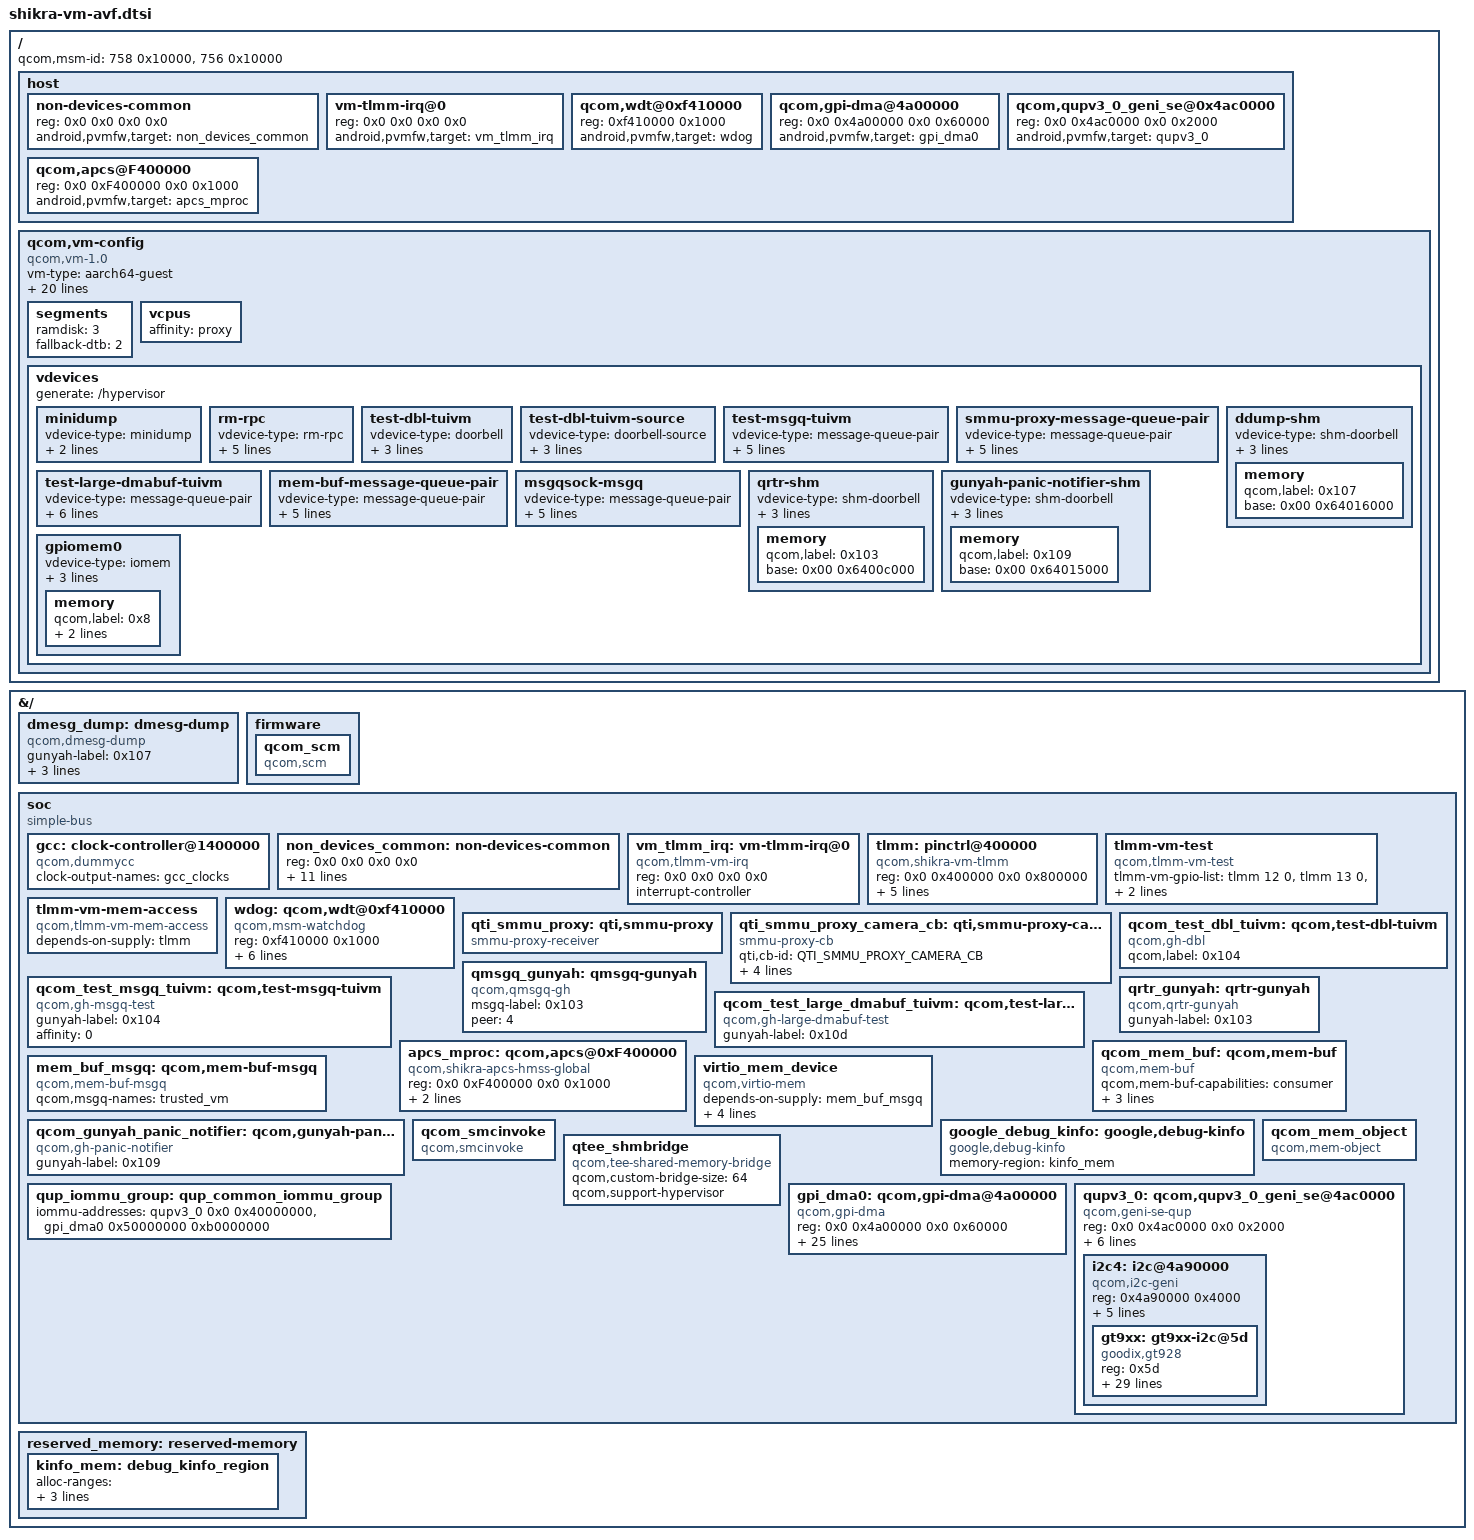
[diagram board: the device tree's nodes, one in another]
// SPDX-License-Identifier: BSD-3-Clause
/*
 * Copyright (c) Qualcomm Technologies, Inc. and/or its subsidiaries.
 */

#include <dt-bindings/interrupt-controller/arm-gic.h>
#include <dt-bindings/arm/msm/qti-smmu-proxy-dt-ids.h>
#include <dt-bindings/clock/qcom,shikra-gcc.h>
#include <dt-bindings/dma/qcom-gpi.h>

/ {
	#address-cells = <0x2>;
	#size-cells = <0x2>;
	qcom,msm-id = <758 0x10000>, <756 0x10000>;

	host {
		#address-cells = <0x2>;
		#size-cells = <0x2>;

		non-devices-common {
			reg = <0x0 0x0 0x0 0x0>;
			android,pvmfw,target = <&non_devices_common>;
		};

		vm-tlmm-irq@0 {
			reg = <0x0 0x0 0x0 0x0>;
			android,pvmfw,target = <&vm_tlmm_irq>;
		};

		qcom,wdt@0xf410000 { // APSS_WDT_TMR1_APSS_WDT
			reg = <0xf410000 0x1000>;
			android,pvmfw,target = <&wdog>;
		};

		qcom,gpi-dma@4a00000 {
			reg = <0x0 0x4a00000 0x0 0x60000>;
			android,pvmfw,target = <&gpi_dma0>;
		};

		qcom,qupv3_0_geni_se@0x4ac0000 {
			reg=<0x0 0x4ac0000 0x0 0x2000>;
			android,pvmfw,target = <&qupv3_0>;
		};

		qcom,apcs@F400000 {
			reg = <0x0 0xF400000 0x0 0x1000>;
			android,pvmfw,target = <&apcs_mproc>;
		};
	};

	qcom,vm-config {
		compatible = "qcom,vm-1.0";
		vm-type = "aarch64-guest";
		boot-config = "fdt,unified";
		// Guest OS
		os-type = "linux";
		kernel-entry-segment = "kernel";
		kernel-entry-offset = <0x0 0x0>;
		vendor = "QTI";
		image-name = "qcom,trustedvm";
		// PIL SW-ID , mandatory for PIL authentication
		qcom,pasid = <0x0 0x1c>;
		// Information for TZ client registration
		qcom,qtee-config-info = "p=3,9,C,39,77,78,7C,8F,96,97,C8,FE,10C,11B,159,199,47E,7F1,CDF;";
		// VMID
		qcom,secdomain-ids = <45>;
		// Index of primary secdomain-id, if qcom,secdomain-ids property present
		qcom,primary-vm-index = <0>;
		vm-uri = "vmuid/trusted-ui";
		// A unique ID that can be used by clients to identify a VM image
		vm-guid = "598085da-c516-5b25-a9c1-927a02819770";
		// Optional – tag VM as sensitive
		qcom,sensitive;

		vm-attrs = "context-dump", "crash-restart", "no-vpm-aggregation";

		/* GPII - 8 is used for QUP LEVM case */
		iomemory-ranges = <0x0 0xF400000 0x0 0xF400000 0x0 0x1000 0x0
				0x0 0x4a30000 0x0 0x4a30000 0x0 0x4000 0x0>;

		/* Dynamically nominate the vmmio ranges */
		vmmio-ranges;

		/* QUP0: SE4: GPII8 : GIC_SPI IRQ 519 + 32 = 551 */
		gic-irq-ranges = <327 327
				551 551>;

		segments {
			ramdisk = <3>;
			// fallback-dtb to support recovery mode
			fallback-dtb = <2>;
		};

		vcpus {
			affinity = "proxy";
		};

		vdevices {
			generate = "/hypervisor";

			// vdevice-type properties herein are specific to host type

			minidump {
				vdevice-type = "minidump";
				push-compatible = "qcom,minidump_rm";
				minidump_allowed;
			};

			rm-rpc {
				// Resource-mgr RPC link
				vdevice-type = "rm-rpc";
				generate = "/hypervisor/qcom,resource-mgr";
				console-dev;
				message-size = <0x000000f0>;
				queue-depth = <0x00000008>;
				qcom,label = <0x1>;
			};

			test-dbl-tuivm {
				vdevice-type = "doorbell";
				generate = "/hypervisor/test-dbl-tuivm";
				qcom,label = <0x104>;
				// Use HLOS VMID as peer
				peer-default;
			};

			test-dbl-tuivm-source {
				vdevice-type = "doorbell-source";
				generate = "/hypervisor/test-dbl-tuivm-source";
				qcom,label = <0x104>;
				peer-default;
			};

			test-msgq-tuivm {
				vdevice-type = "message-queue-pair";
				generate = "/hypervisor/test-msgq-tuivm-pair";
				message-size = <0xf0>;
				queue-depth = <0x8>;
				qcom,label = <0x104>;
				peer-default;
			};
			smmu-proxy-message-queue-pair {
				vdevice-type = "message-queue-pair";
				generate = "/hypervisor/smmu-proxy-msgq-pair";
				message-size = <0x000000f0>;
				queue-depth = <0x00000008>;
				peer-default;
				qcom,label = <0x10a>;
			};

			test-large-dmabuf-tuivm {
				vdevice-type = "message-queue-pair";
				generate = "/hypervisor/test-large-dmabuf-tuivm-pair";
				message-size = <0xf0>;
				queue-depth = <0x8>;
				qcom,label = <0x10d>;
				peer-default;
			};

			mem-buf-message-queue-pair {
				vdevice-type = "message-queue-pair";
				generate = "/hypervisor/membuf-msgq-pair";
				message-size = <0x000000f0>;
				queue-depth = <0x00000008>;
				peer-default;
				qcom,label = <0x101>;
			};

			msgqsock-msgq {
				vdevice-type = "message-queue-pair";
				generate = "/hypervisor/msgqsock-msgq-pair";
				message-size = <0xf0>;
				queue-depth = <0x8>;
				peer = "vm-name:qcom,oemvm";
				qcom,label = <0x103>;
			};

			ddump-shm {
				vdevice-type = "shm-doorbell";
				generate = "/hypervisor/ddump-shm";
				push-compatible = "qcom,ddump-gunyah-gen";
				peer-default;
				memory {
					qcom,label = <0x107>;
					#address-cells = <0x2>;
					base = <0x00 0x64016000>;
				};
			};

			qrtr-shm {
				vdevice-type = "shm-doorbell";
				generate = "/hypervisor/qrtr-shm";
				push-compatible = "qcom,qrtr-gunyah-gen";
				peer-default;
				memory {
					qcom,label = <0x103>;
					#address-cells = <0x2>;
					base = <0x00 0x6400c000>;
				};
			};

			gunyah-panic-notifier-shm {
				vdevice-type = "shm-doorbell";
				generate = "/hypervisor/gpn-shm";
				push-compatible = "qcom,gunyah-panic-gen";
				peer-default;
				memory {
					qcom,label = <0x109>;
					#address-cells = <0x2>;
					base = <0x00 0x64015000>;
				};
			};

			gpiomem0 {
				// Generate an iomem device
				vdevice-type = "iomem";
				patch = "/soc/tlmm-vm-mem-access";
				push-compatible = "qcom,tlmm-vm-mem-access";
				peer-default;
				memory {
					// Reference a memparcel by label
					qcom,label = <0x8>;
					qcom,mem-info-tag = <0x3>;
					// Allocate from VM IPA address space (currently IPA=PA)
					allocate-base;
				};
			};
		};
	};
};

&{/} {
	dmesg_dump: dmesg-dump {
		compatible = "qcom,dmesg-dump";
		gunyah-label = <0x107>;
		ddump-pubkey-size = <270>;
		ddump-pubkey = /bits/ 8 <0x30 0x82 0x01 0x0a 0x02 0x82 0x01 0x01 0x00 0xe6 0x4b 0x31 0x82 0x61 0x14 0xf2
				0xbe 0xd1 0xe4 0xde 0xe7 0xed 0xba 0x8f 0x3b 0x23 0x5f 0x7a 0xb8 0x16 0x40 0x96
				0xae 0x77 0x5e 0x1b 0xf0 0x3f 0x39 0xab 0x69 0x90 0xb1 0xd4 0x70 0xcb 0x66 0xbc
				0x41 0x08 0x1d 0x37 0xdb 0x49 0xc8 0x49 0x5b 0x99 0x5c 0x32 0xbe 0x62 0xd5 0xa7
				0x3c 0x0f 0xa4 0x4b 0x43 0x49 0xdb 0x54 0x69 0x06 0x0c 0xe5 0x99 0xe5 0xf9 0x1e
				0x25 0x84 0x17 0x47 0x62 0x2b 0x5d 0x0d 0xec 0x5e 0xc6 0xb5 0x86 0xb9 0x75 0x6d
				0xfe 0x7d 0x35 0x4f 0x35 0xc1 0x48 0x10 0x75 0x4c 0x57 0x6b 0x46 0x4b 0xff 0x5b
				0x52 0x22 0x40 0x2c 0xb0 0x47 0xe1 0x47 0xc4 0xe5 0x47 0x0c 0x56 0xe8 0x17 0xd0
				0x7e 0xc3 0x4d 0x9f 0xea 0xd0 0xea 0x87 0xe5 0x51 0x39 0xe8 0x45 0x4c 0x54 0x27
				0x9c 0x50 0x38 0xb7 0x72 0x93 0x12 0x0b 0xa1 0x2f 0x9e 0x04 0x92 0x20 0x6e 0x31
				0x42 0x87 0xe1 0xfe 0x88 0x3f 0xe5 0x09 0xe1 0xf9 0xbe 0x44 0xc6 0xbf 0x10 0x79
				0x36 0x47 0x7b 0xa0 0x8e 0x27 0x31 0xa3 0x70 0x69 0x01 0x54 0x92 0xf4 0x42 0xbd
				0xcd 0x7e 0x79 0x2b 0x2c 0xe1 0xd4 0xba 0x6e 0x34 0xc6 0xe6 0xc6 0x5c 0x63 0xd0
				0x7f 0x39 0x1f 0xe8 0x8d 0x67 0xe6 0x27 0x67 0x0d 0x16 0x57 0x94 0xd1 0xfb 0xdf
				0xce 0xaf 0xfd 0x43 0xb3 0xbe 0x5d 0x83 0x4b 0x93 0x05 0xe8 0xdf 0x04 0xad 0xac
				0xeb 0xa6 0x81 0xa7 0xd5 0x04 0x63 0xbf 0x83 0xb8 0x0c 0xbc 0x20 0x18 0xb5 0x50
				0xd7 0x61 0x84 0x11 0xca 0x2d 0x22 0xb3 0x29 0x02 0x03 0x01 0x00 0x01>;
	};

	firmware: firmware {
		qcom_scm: qcom_scm {
			compatible = "qcom,scm";
		};
	};

	soc: soc { };

	reserved_memory: reserved-memory {
		#address-cells = <2>;
		#size-cells = <2>;
		ranges;
	};
};

&reserved_memory {
	kinfo_mem: debug_kinfo_region {
		alloc-ranges = <0x0 0x00000000 0xffffffff 0xffffffff>;
		size = <0x0 0x1000>;
		no-map;
	};
};

&soc {
	#address-cells = <2>;
	#size-cells = <2>;
	ranges;
	compatible = "simple-bus";

	gcc: clock-controller@1400000 {
		compatible = "qcom,dummycc";
		clock-output-names = "gcc_clocks";
		#clock-cells = <1>;
		#reset-cells = <1>;
	};

	/*
	 * Refer all non device nodes which are already not referred by a device node
	 * Some of the non device nodes might be already a dependency.
	 * So they are not added in this.
	 */
	non_devices_common: non-devices-common {
		reg = <0x0 0x0 0x0 0x0>;
		required-subnodes = <&qcom_scm
			&dmesg_dump
			&kinfo_mem
			&qcom_dma_heaps
			&qcom_test_dbl_tuivm
			&qcom_test_msgq_tuivm
			&qcom_test_large_dmabuf_tuivm
			&qcom_mem_buf
			&qrtr_gunyah
			&qmsgq_gunyah
			&mem_buf_msgq
			&virtio_mem_device
			&qcom_gunyah_panic_notifier
			&google_debug_kinfo
			&qcom_smcinvoke
			&qcom_mem_object
			&qtee_shmbridge
			&qti_smmu_proxy
			&qti_smmu_proxy_camera_cb
			&tlmm>;
	};

	vm_tlmm_irq: vm-tlmm-irq@0 {
		compatible = "qcom,tlmm-vm-irq";
		reg = <0x0 0x0 0x0 0x0>;
		interrupt-controller;
		#interrupt-cells = <2>;
	};

	tlmm: pinctrl@400000 {
		compatible = "qcom,shikra-vm-tlmm";
		reg = <0x0 0x400000 0x0 0x800000>;
		interrupts-extended = <&vm_tlmm_irq 1 IRQ_TYPE_LEVEL_HIGH>;
		gpio-controller;
		#gpio-cells = <2>;
		interrupt-controller;
		#interrupt-cells = <2>;
		gpios = /bits/ 16 <3 12 13 76 85 86 91 151>;
	};

	tlmm-vm-test {
		compatible = "qcom,tlmm-vm-test";
		tlmm-vm-gpio-list = <&tlmm 12 0 &tlmm 13 0 &tlmm 3 0 &tlmm 76 0
					&tlmm 85 0 &tlmm 86 0 &tlmm 91 0 &tlmm 151 0>;
	};

	pinctrl@400000 {
	};

	tlmm-vm-mem-access {
		compatible = "qcom,tlmm-vm-mem-access";
		depends-on-supply = <&tlmm>;
	};

	wdog: qcom,wdt@0xf410000 {  // Same as PVM
		compatible = "qcom,msm-watchdog";
		reg = <0xf410000 0x1000>;
		reg-names = "wdt-base";
		interrupts = <GIC_SPI 0 IRQ_TYPE_LEVEL_HIGH>,
			     <GIC_SPI 1 IRQ_TYPE_LEVEL_HIGH>;
		qcom,bark-time = <11000>;
		qcom,pet-time = <9360>;
		qcom,ipi-ping;
		qcom,wakeup-enable;
		status="ok";
	};

	qti_smmu_proxy: qti,smmu-proxy {
		compatible = "smmu-proxy-receiver";
	};

	qti_smmu_proxy_camera_cb: qti,smmu-proxy-camera-cb {
		compatible = "smmu-proxy-cb";
		qti,cb-id = <QTI_SMMU_PROXY_CAMERA_CB>;
		qcom,iommu-defer-smr-config;
		iommus = <&apps_smmu 0x601 0x0>,
			 <&apps_smmu 0x621 0x0>,
			 <&apps_smmu 0x641 0x0>,
			 <&apps_smmu 0x401 0x0>;
	};

	qcom_test_dbl_tuivm: qcom,test-dbl-tuivm {
		compatible = "qcom,gh-dbl";
		qcom,label = <0x104>;
	};

	qcom_test_msgq_tuivm: qcom,test-msgq-tuivm {
		compatible = "qcom,gh-msgq-test";
		gunyah-label = <0x104>;
		affinity = <0>;
	};

	qmsgq_gunyah: qmsgq-gunyah {
		compatible = "qcom,qmsgq-gh";
		msgq-label = <0x103>;
		peer = <4>;
	};

	qrtr_gunyah: qrtr-gunyah {
	      compatible = "qcom,qrtr-gunyah";
	      gunyah-label = <0x103>;
	};

	qcom_test_large_dmabuf_tuivm: qcom,test-large-dmabuf-tuivm {
		compatible = "qcom,gh-large-dmabuf-test";
		gunyah-label = <0x10d>;
	};

	apcs_mproc: qcom,apcs@0xF400000 {
		compatible = "qcom,shikra-apcs-hmss-global";
		reg = <0x0 0xF400000 0x0 0x1000>;
		interrupts = <GIC_SPI 295 IRQ_TYPE_LEVEL_HIGH>;
		interrupt-controller;
		#interrupt-cells = <3>;
		#mbox-cells = <2>;
	};

	qcom_mem_buf: qcom,mem-buf {
		compatible = "qcom,mem-buf";
		qcom,mem-buf-capabilities = "consumer";
		qcom,ipa-range = <0x0 0x0 0xf 0xffffffff>;
		qcom,dmabuf-ipa-size = <0x3 0xA0000000>; /* 14GB IPA space for dmabuf */
		qcom,vmid = <45>;
	};

	mem_buf_msgq: qcom,mem-buf-msgq {
		compatible = "qcom,mem-buf-msgq";
		qcom,msgq-names = "trusted_vm";
	};

	virtio_mem_device: virtio_mem_device {
		compatible = "qcom,virtio-mem";
		depends-on-supply = <&mem_buf_msgq>;
		/* Must be memory_block_size_bytes() aligned */
		qcom,max-size = <0x0 0x18000000>;
		qcom,ipa-range = <0x0 0x0 0xf 0xffffffff>;
		qcom,block-size = <0x400000>;
		qcom,initial-movable-zone-size = <0x2000000>;
	};

	qcom_gunyah_panic_notifier: qcom,gunyah-panic-notifier {
		compatible = "qcom,gh-panic-notifier";
		gunyah-label = <0x109>;
	};

	google_debug_kinfo: google,debug-kinfo {
		compatible = "google,debug-kinfo";
		memory-region = <&kinfo_mem>;
	};

	qcom_smcinvoke: qcom_smcinvoke {
		compatible = "qcom,smcinvoke";
	};

	qcom_mem_object: qcom_mem_object {
		compatible = "qcom,mem-object";
	};

	qtee_shmbridge: qtee_shmbridge {
		compatible = "qcom,tee-shared-memory-bridge";
		qcom,custom-bridge-size = <64>;
		qcom,support-hypervisor;
	};

	qup_iommu_group: qup_common_iommu_group {
		iommu-addresses = <&qupv3_0 0x0 0x40000000>,
				  <&gpi_dma0 0x50000000 0xb0000000>;
	};

	gpi_dma0: qcom,gpi-dma@4a00000 {
		compatible = "qcom,gpi-dma";
		#dma-cells = <5>;
		reg = <0x0 0x4a00000 0x0 0x60000>;
		reg-names = "gpi-top";
		iommus = <&apps_smmu 0xf8 0x0>;
		qcom,iommu-group = <&qup_iommu_group>;
		memory-region = <&qup_iommu_group>;
		interrupts = <GIC_SPI 511 IRQ_TYPE_LEVEL_HIGH>,
			     <GIC_SPI 512 IRQ_TYPE_LEVEL_HIGH>,
			     <GIC_SPI 513 IRQ_TYPE_LEVEL_HIGH>,
			     <GIC_SPI 514 IRQ_TYPE_LEVEL_HIGH>,
			     <GIC_SPI 515 IRQ_TYPE_LEVEL_HIGH>,
			     <GIC_SPI 516 IRQ_TYPE_LEVEL_HIGH>,
			     <GIC_SPI 517 IRQ_TYPE_LEVEL_HIGH>,
			     <GIC_SPI 518 IRQ_TYPE_LEVEL_HIGH>,
			     <GIC_SPI 519 IRQ_TYPE_LEVEL_HIGH>,
			     <GIC_SPI 520 IRQ_TYPE_LEVEL_HIGH>,
			     <GIC_SPI 521 IRQ_TYPE_LEVEL_HIGH>,
			     <GIC_SPI 522 IRQ_TYPE_LEVEL_HIGH>,
			     <GIC_SPI 523 IRQ_TYPE_LEVEL_HIGH>,
			     <GIC_SPI 524 IRQ_TYPE_LEVEL_HIGH>,
			     <GIC_SPI 525 IRQ_TYPE_LEVEL_HIGH>,
			     <GIC_SPI 526 IRQ_TYPE_LEVEL_HIGH>;
		qcom,max-num-gpii = <16>;
		qcom,static-gpii-mask = <0x100>;
		qcom,gpii-mask = <0x0>;
		qcom,ev-factor = <1>;
		qcom,gpi-ee-offset = <0x10000>;
		qcom,le-vm;
		status = "ok";
	};

	qupv3_0: qcom,qupv3_0_geni_se@4ac0000 {
		compatible = "qcom,geni-se-qup";
		reg = <0x0 0x4ac0000 0x0 0x2000>;
		#address-cells = <1>;
		#size-cells = <1>;
		clock-names = "m-ahb", "s-ahb";
		clocks = <&gcc GCC_QUPV3_WRAP_0_M_AHB_CLK>,
			 <&gcc GCC_QUPV3_WRAP_0_S_AHB_CLK>;
		iommus = <&apps_smmu 0xf8 0x0>;
		qcom,iommu-group = <&qup_iommu_group>;
		memory-region = <&qup_iommu_group>;
		ranges;
		status = "ok";
		required-subnodes = <&i2c4>;

		i2c4: i2c@4a90000 {
			compatible = "qcom,i2c-geni";
			reg = <0x4a90000 0x4000>;
			dmas = <&gpi_dma0 0 4 QCOM_GPI_I2C 64 0x12>,
			       <&gpi_dma0 1 4 QCOM_GPI_I2C 64 0x12>;
			dma-names = "tx",
				    "rx";
			#address-cells = <1>;
			#size-cells = <0>;
			qcom,le-vm;
			status = "disabled";
		};
	};
};

#include "msm-arm-smmu-shikra-vm-avf.dtsi"
#include "shikra-vm-dma-heaps-avf.dtsi"
#include "shikra-vm-rm-info-avf.dtsi"

&i2c4 {
	status = "ok";
	qcom,touch-active = "goodix,gt928";
	required-subnodes = <&gt9xx>;

	gt9xx: gt9xx-i2c@5d {
		compatible = "goodix,gt928";
		reg = <0x5d>;
		status = "okay";
		touchscreen-max-id = <11>;
		touchscreen-size-x = <1080>;
		touchscreen-size-y = <1920>;
		touchscreen-max-w = <1024>;
		touchscreen-max-p = <1024>;
		goodix,type-a-report = <0>;
		goodix,driver-send-cfg = <1>;
		goodix,create-wr-node = <1>;
		goodix,wakeup-with-reset = <0>;
		goodix,resume-in-workqueue = <0>;
		goodix,int-sync = <1>;
		goodix,swap-x2y = <0>;
		goodix,esd-protect = <1>;
		goodix,pen-suppress-finger = <0>;
		goodix,auto-update = <0>;
		goodix,auto-update-cfg = <0>;
		goodix,power-off-sleep = <0>;
		goodix,touch-type = "primary";
		goodix,cfg-group0 = [
			42 38 04 80 07 0A 35 00 01 08 32 05 50 3C 03 05 00 00 00 00 00 00 00 18 1A 1E 14 8C 2E 0E
			32 34 7F 08 00 00 01 BB 02 1D 00 00 00 00 00 03 64 32 00 00 00 23 46 94 C5 02 00 00 00 00
			A7 25 00 92 2B 00 82 31 00 74 38 00 66 41 00 66 00 00 00 00 00 00 00 00 00 00 00 00 00 00
			00 00 00 00 00 00 00 00 00 00 00 00 00 00 00 00 00 00 00 00 00 00 1C 1A 18 16 14 12 10 0E
			0C 0A 08 06 04 02 00 00 00 00 00 00 00 00 00 00 00 00 00 00 00 00 00 02 04 06 08 0A 0C 0F
			10 12 13 14 16 2A 29 28 26 24 22 21 20 1F 1E 1D 1C 18 00 00 00 00 00 00 00 00 00 00 00 00
			00 00 00 00 82 01];

		goodix,qts_en;
		qts,trusted-touch-mode = "vm_mode";
		qts,touch-environment = "tvm";
		qts,trusted-touch-type = "primary";
		qts,trusted-touch-spi-irq = <267>;
		qts,trusted-touch-io-bases = <0x4a90000>;
		qts,trusted-touch-io-sizes = <0x1000>;
		qts,trusted-touch-vm-gpio-list = <&tlmm 12 0 &tlmm 13 0 &tlmm 76 0 &tlmm 85 0x2008>;
	};
};
